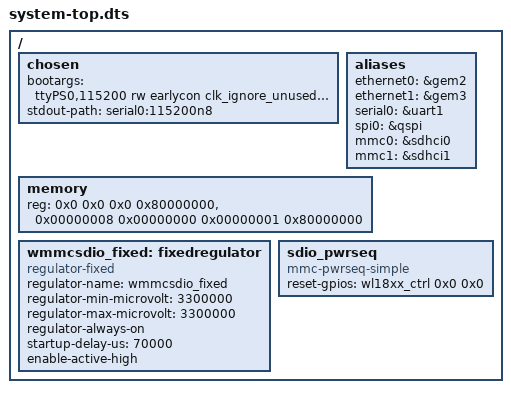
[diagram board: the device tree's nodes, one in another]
/*
 * CAUTION: This file is automatically generated by Xilinx.
 * Version: XSCT 2018.3
 * Today is: Fri Feb  1 14:32:24 2019
 */


/dts-v1/;
/include/ "zynqmp.dtsi"
/include/ "zynqmp-clk-ccf.dtsi"
/include/ "pl.dtsi"
/include/ "pcw.dtsi"
/ {
	chosen {
		bootargs = "ttyPS0,115200 rw earlycon clk_ignore_unused root=/dev/ram0 earlyprintk uio_pdrv_genirq.of_id=xlnx,generic-uio cma=1024M";
		stdout-path = "serial0:115200n8";
	};
	aliases {
		ethernet0 = &gem2;
		ethernet1 = &gem3;
		serial0 = &uart1;
		spi0 = &qspi;
		mmc0 = &sdhci0;
		mmc1 = &sdhci1;
	};
	memory {
		device_type = "memory";
		reg = <0x0 0x0 0x0 0x80000000>, <0x00000008 0x00000000 0x00000001 0x80000000>;
	};
	
	wmmcsdio_fixed: fixedregulator {
      compatible = "regulator-fixed";
      regulator-name = "wmmcsdio_fixed";
      regulator-min-microvolt = <3300000>;
      regulator-max-microvolt = <3300000>;      
      regulator-always-on;
      startup-delay-us = <70000>;
      enable-active-high;
   };
   
   sdio_pwrseq: sdio_pwrseq {
      compatible = "mmc-pwrseq-simple";
      reset-gpios = <&wl18xx_ctrl 0x0 0x0 0x0>;
   };
};
